AUTOSAR XML (schema 4-3-0)
package /CollisionDetectionBSW/Services/IoHwAb
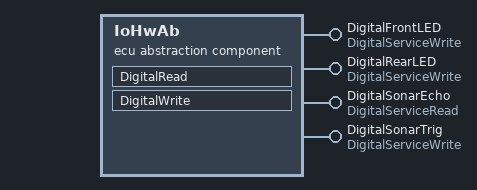
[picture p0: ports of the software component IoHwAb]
  ecu abstraction sw component type IoHwAb
    4 x provide port:
      DigitalFrontLED: provided-interface=DigitalServiceWrite
      DigitalRearLED: provided-interface=DigitalServiceWrite
      DigitalSonarEcho: provided-interface=DigitalServiceRead
      DigitalSonarTrig: provided-interface=DigitalServiceWrite
    behavior IoHwAbBehavior: handle-termination-and-restart=NO-SUPPORT
      4 x operation invoked event:
        DigitalRead_DigitalSonarEcho_Read: start-on-event=DigitalRead, operation=DigitalSonarEcho.Read
        DigitalWrite_DigitalFrontLED_Write: start-on-event=DigitalWrite, operation=DigitalFrontLED.Write
        DigitalWrite_DigitalRearLED_Write: start-on-event=DigitalWrite, operation=DigitalRearLED.Write
        DigitalWrite_DigitalSonarTrig_Write: start-on-event=DigitalWrite, operation=DigitalSonarTrig.Write
      port-api-options:
        {port-defined-argument-value{value=IoHwAb_SignalType_:0, value-type=IoHwAb_SignalType_}, port=DigitalFrontLED}
        {port-defined-argument-value{value=IoHwAb_SignalType_:1, value-type=IoHwAb_SignalType_}, port=DigitalRearLED}
        {port-defined-argument-value{value=IoHwAb_SignalType_:2, value-type=IoHwAb_SignalType_}, port=DigitalSonarEcho}
        {port-defined-argument-value{value=IoHwAb_SignalType_:3, value-type=IoHwAb_SignalType_}, port=DigitalSonarTrig}
      runnable DigitalRead: can-be-invoked-concurrently=true, symbol=IoHwAb_Digital_Read
      runnable DigitalWrite: can-be-invoked-concurrently=true, symbol=IoHwAb_Digital_Write
  swc implementation IoHwAbImpl: programming-language=C, vendor-id=60, behavior=IoHwAbBehavior
    code-descriptors:
      code src: artifact-descriptors=autosar-engineering-object={short-label=artifactDescriptor, category=artifactDescriptorCategory}
    resource consumption resourceConsumption
